# STM32H7S7xx register map
File version: 1.0
Registers are 32-bit, read-write, reset 0x0 unless marked. A register's access mark holds for its fields unless they carry their own. Offsets are from the block's base; [hi:lo] are bit positions; {n}, {i} and the like mark numbered series; 'fields as' and 'values as' point back to an identical list.

## FMC_Bank5_6_R — Flexible Memory Controller Bank5 & 6
Base 0x52004140
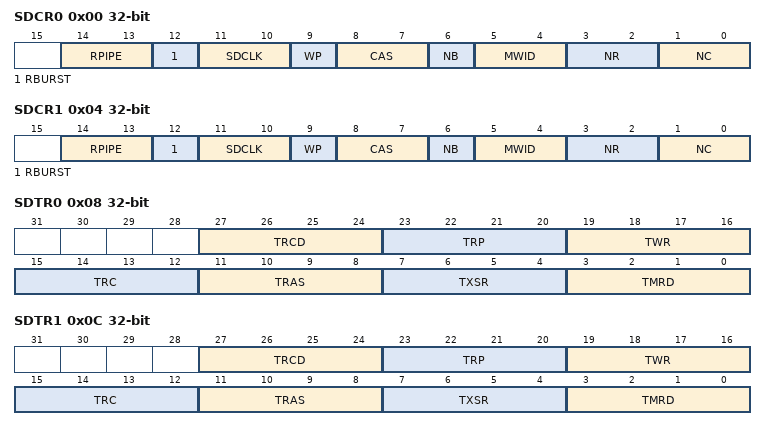
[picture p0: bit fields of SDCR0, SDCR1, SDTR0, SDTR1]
0x00 SDCR0 — SDRAM Control registers
  [14:13] RPIPE — Read pipe
  [12] RBURST — Read burst
  [11:10] SDCLK — SDRAM clock configuration
  [9] WP — Write protection
  [8:7] CAS — CAS latency
  [6] NB — Number of internal banks
  [5:4] MWID — Memory data bus width
  [3:2] NR — Number of row address bits
  [1:0] NC — Number of column address bits
0x04 SDCR1 — SDRAM Control registers
  fields as SDCR0
0x08 SDTR0 — SDRAM Timing registers
  [27:24] TRCD — Row to column delay
  [23:20] TRP — Row precharge delay
  [19:16] TWR — Recovery delay
  [15:12] TRC — Row cycle delay
  [11:8] TRAS — Self refresh time
  [7:4] TXSR — Exit self-refresh delay
  [3:0] TMRD — Load mode register to active
0x0C SDTR1 — SDRAM Timing registers
  fields as SDTR0
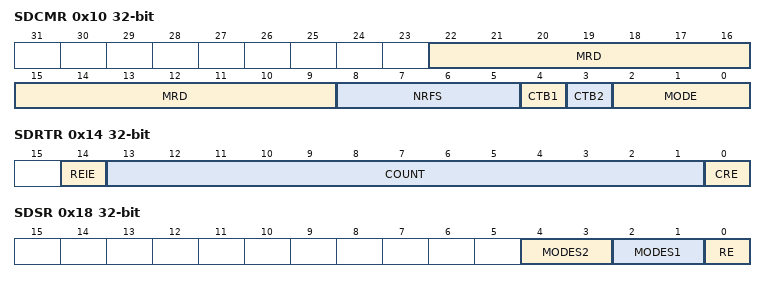
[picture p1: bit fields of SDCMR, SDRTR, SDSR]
0x10 SDCMR — SDRAM Command Mode register
  [22:9] MRD — Mode register definition
  [8:5] NRFS — Number of auto-refresh
  [4] CTB1 — Command target bank 1
  [3] CTB2 — Command target bank 2
  [2:0] MODE — Command mode
0x14 SDRTR — SDRAM Refresh Timer register
  [14] REIE — RES interrupt enable
  [13:1] COUNT — Refresh timer count
  [0] CRE — Clear refresh error flag
0x18 SDSR — SDRAM Status register
  [4:3] MODES2 — Status mode for bank 2
  [2:1] MODES1 — Status mode for bank 1
  [0] RE — Refresh error flag

## RAMECC1
Base 0x52009000
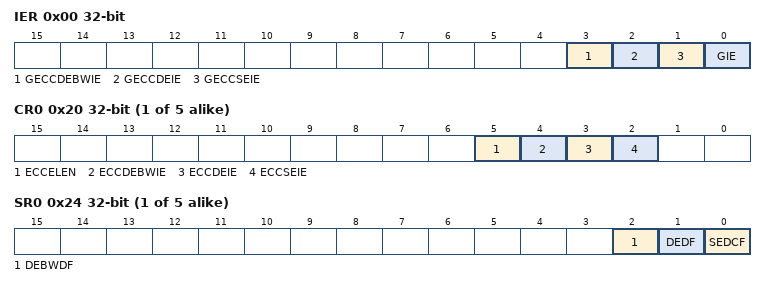
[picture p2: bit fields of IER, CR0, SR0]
0x00 IER — RAMECC interrupt enable register
  [3] GECCDEBWIE — Global ECC double error on byte write (BW) interrupt enable
  [2] GECCDEIE — Global ECC double error interrupt enable
  [1] GECCSEIE — Global ECC single error interrupt enable
  [0] GIE — Global interrupt enable
{0x20+0x20*i} CR{i} (i=0..4) — RAMECC monitor configuration register
  [5] ECCELEN — ECC error latching enable
  [4] ECCDEBWIE — ECC double error on byte write (BW) interrupt enable
  [3] ECCDEIE — ECC double error interrupt enable
  [2] ECCSEIE — ECC single error interrupt enable
{0x24+0x20*i} SR{i} (i=0..4) — RAMECC monitor status register
  [2] DEBWDF — ECC double error on byte write (BW) detected flag
  [1] DEDF — ECC double error detected flag
  [0] SEDCF — ECC single error detected and corrected flag
{0x28+0x20*i} FAR{i} (i=0..4) — RAMECC monitor failing address register
  [31:0] FADD — ECC error failing address
{0x2C+0x20*i} FDRL{i} (i=0..4) — RAMECC monitor failing data low register
  [31:0] FDATAL — Failing data low
{0x30+0x20*i} FDRH{i} (i=0..4) — RAMECC monitor failing data high register
  [31:0] FDATAH
{0x34+0x20*i} FECR{i} (i=0..4) — RAMECC monitor failing ECC error code register
  [31:0] FEC — Failing error code

## RAMECC2
Base 0x58027000
Registers as RAMECC1, without CR0, SR0, FAR0, FDRL0, FDRH0, FECR0, CR{n} (n=2..4), SR{n} (n=2..4), FAR{n} (n=2..4), FDRL{n} (n=2..4), FDRH{n} (n=2..4), FECR{n} (n=2..4).

## XSPIM — XSPI IO Manager
Base 0x5200B400
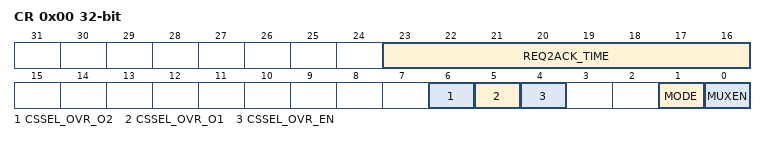
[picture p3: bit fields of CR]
0x00 CR — XSPIM IO Manager Control Register
  [23:16] REQ2ACK_TIME — REQ to ACK Time
  [6] CSSEL_OVR_O2 — Chip select selector override setting for XSPI2
  [5] CSSEL_OVR_O1 — Chip select selector override setting for XSPI1
  [4] CSSEL_OVR_EN — Chip select selector override enable
  [1] MODE — Multiplexing Mode
  [0] MUXEN — Multiplexed Mode Enable

## MCE1
Base 0x5200B800
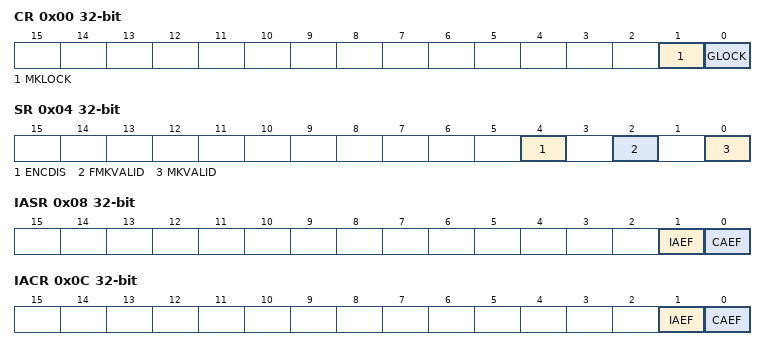
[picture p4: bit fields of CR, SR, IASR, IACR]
0x00 CR — MCE configuration register
  [1] MKLOCK — MCE master and fast master keys lock
  [0] GLOCK — MCE global lock
0x04 SR — MCE status register
  [4] ENCDIS — MCE encryption disabled flag
  [2] FMKVALID — MCE fast master key valid flag
  [0] MKVALID — MCE master key valid flag
0x08 IASR — MCE illegal access status register
  [1] IAEF — MCE illegal access error flag
  [0] CAEF — MCE configuration access error flag
0x0C IACR — MCE illegal access clear register
  [1] IAEF — MCE illegal access error clear bit
  [0] CAEF — MCE configuration access error clear bit
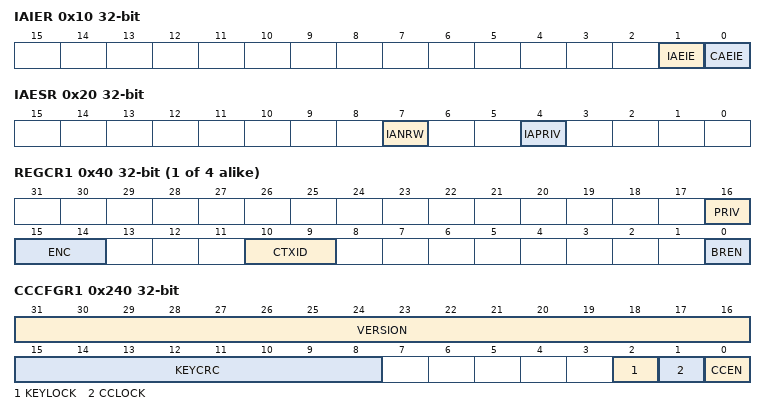
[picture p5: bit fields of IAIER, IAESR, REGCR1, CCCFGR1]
0x10 IAIER — MCE illegal access interrupt enable register
  [1] IAEIE — MCE illegal access error interrupt enable
  [0] CAEIE — MCE configuration access error interrupt enable
0x1C PRIVCFGR — MCE privileged configuration register
  [0] PRIV — MCE privileged configuration
0x20 IAESR — MCE illegal access error status register
  [7] IANRW — MCE illegal access read/write
  [4] IAPRIV — MCE illegal access privilege
0x24 IADDR — MCE illegal address register
  [31:0] IADD — MCE illegal address
{0x30+0x10*i} REGCR{i} (i=1..4) — MCE region configuration register
  [16] PRIV — MCE privileged region
  [15:14] ENC — MCE encrypted region
  [10:9] CTXID — MCE context ID
  [0] BREN — MCE base region enable
{0x34+0x10*i} SADDR{i} (i=1..4) — MCE region start address register
  [31:12] BADDSTART — MCE region address start
{0x38+0x10*i} EADDR{i} (i=1..4) — MCE region end address register
  [31:12] BADDEND — MCE region address end
{0x3C+0x10*i} ATTR{i} (i=1..4) — MCE region attribute register
  [16] WREN — MCE region write enable
{0x200+4i} MKEYR{i} (i=0..3) — MCE master key register {i}
  [31:0] MKEY — MCE master key, bits [{32i+31}:{32i}]
{0x220+4i} FMKEYR{i} (i=0..3) — MCE fast master key register {i}
  [31:0] FMKEY — MCE fast master key, bits [{32i+31}:{32i}]
0x240 CCCFGR1 — MCE cipher context configuration register
  [31:16] VERSION — MCE cipher context version
  [15:8] KEYCRC — MCE cipher context key CRC
  [2] KEYLOCK — MCE cipher context key lock
  [1] CCLOCK — MCE cipher context lock
  [0] CCEN — MCE cipher context enable
0x244 CCNR01 — MCE cipher context nonce register 0
  [31:0] SCNONCE — MCE cipher context stream cipher nonce, bits [31:0]
0x248 CCNR1 — MCE cipher context nonce register 1
  [31:0] SCNONCE — MCE cipher context stream cipher nonce, bits [63:32]
0x24C CCKEYR01 — MCE cipher context key register 0
  [31:0] KEY — MCE cipher context key, bits [31:0]
0x250 CCKEYR1 — MCE cipher context key register 1
  [31:0] KEY — MCE fast master key, bits [63:32]
0x254 CCKEYR21 — MCE cipher context key register 2
  [31:0] KEY — MCE fast master key, bits [95:64]
0x258 CCKEYR31 — MCE cipher context key register 3
  [31:0] KEY — MCE fast master key, bits [127:96]
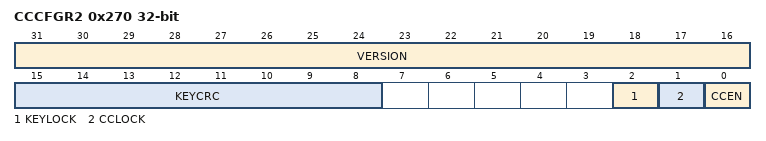
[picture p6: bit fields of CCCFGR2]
0x270 CCCFGR2 — MCE cipher context configuration register
  fields as CCCFGR1
0x274 CCNR02 — MCE cipher context nonce register 0
  [31:0] SCNONCE — MCE cipher context stream cipher nonce, bits [31:0]
0x278 CCNR12 — MCE cipher context nonce register 1
  fields as CCNR1
0x27C CCKEYR02 — MCE cipher context key register 0
  [31:0] KEY — MCE cipher context key, bits [31:0]
0x280 CCKEYR12 — MCE cipher context key register 1
  [31:0] KEY — MCE fast master key, bits [63:32]
0x284 CCKEYR2 — MCE cipher context key register 2
  [31:0] KEY — MCE fast master key, bits [95:64]
0x288 CCKEYR32 — MCE cipher context key register 3
  [31:0] KEY — MCE fast master key, bits [127:96]

## MCE2
Base 0x5200BC00
Same registers: MCE3 0x5200C000
Registers as MCE1, without CCCFGR1, CCNR01, CCNR1, CCKEYR01, CCKEYR1, CCKEYR21, CCKEYR31, CCCFGR2, CCNR02, CCNR12, CCKEYR02, CCKEYR12, CCKEYR2, CCKEYR32.
